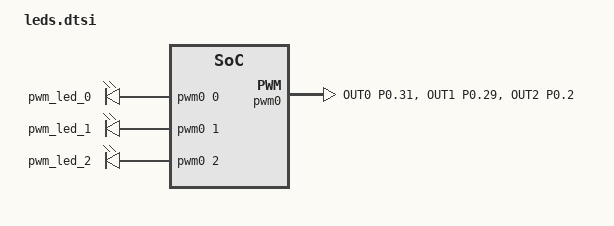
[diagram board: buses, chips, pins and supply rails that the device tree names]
/ {
    backlight: pwmleds {
        compatible = "pwm-leds";
        pwm_led_0: pwm_led_0 {
            pwms = <&pwm0 0 PWM_MSEC(10) PWM_POLARITY_NORMAL>;
        };
        pwm_led_1: pwm_led_1 {
            pwms = <&pwm0 1 PWM_MSEC(10) PWM_POLARITY_NORMAL>;
        };
        pwm_led_2: pwm_led_2 {
            pwms = <&pwm0 2 PWM_MSEC(10) PWM_POLARITY_NORMAL>;
        };
    };

    aliases {
        led0 = &pwm_led_0;
        led1 = &pwm_led_1;
        led2 = &pwm_led_2;
    };
};

&pinctrl {
    // Other Pinctrl definitions go here
    pwm0_default: pwm0_default {
        group1 {
            psels = <NRF_PSEL(PWM_OUT0, 0, 31)>, // LED 0
                    <NRF_PSEL(PWM_OUT1, 0, 29)>, // LED 1
                    <NRF_PSEL(PWM_OUT2, 0, 2)>;  // LED 2
        };
    };
    pwm0_sleep: pwm0_sleep {
        group1 {
            psels = <NRF_PSEL(PWM_OUT0, 0, 31)>, // LED 0
                    <NRF_PSEL(PWM_OUT1, 0, 29)>, // LED 1
                    <NRF_PSEL(PWM_OUT2, 0, 2)>;  // LED 2
            low-power-enable;
        };
    };
};

&pwm0 {
    status = "okay";
    pinctrl-0 = <&pwm0_default>;
    pinctrl-1 = <&pwm0_sleep>;
    pinctrl-names = "default", "sleep";
};
